# EFM32GG12B810F1024IL120 register map
File version: 3.0.0
CPU: CM4 r0p1, little endian, MPU, FPU, 3 interrupt priority bits
Registers are 32-bit, read-write, reset 0x0 unless marked. A register's access mark holds for its fields unless they carry their own. Offsets are from the block's base; [hi:lo] are bit positions; {n}, {i} and the like mark numbered series.

## SMU
Base 0x40020000
0x0C IF ro — Interrupt Flag Register
  [0] PPUPRIV — PPU Privilege Interrupt Flag
0x10 IFS wo — Interrupt Flag Set Register
  [0] PPUPRIV — Set PPUPRIV Interrupt Flag
0x14 IFC wo — Interrupt Flag Clear Register
  [0] PPUPRIV — Clear PPUPRIV Interrupt Flag
0x18 IEN — Interrupt Enable Register
  [0] PPUPRIV — PPUPRIV Interrupt Enable
0x40 PPUCTRL — PPU Control Register
  [0] ENABLE
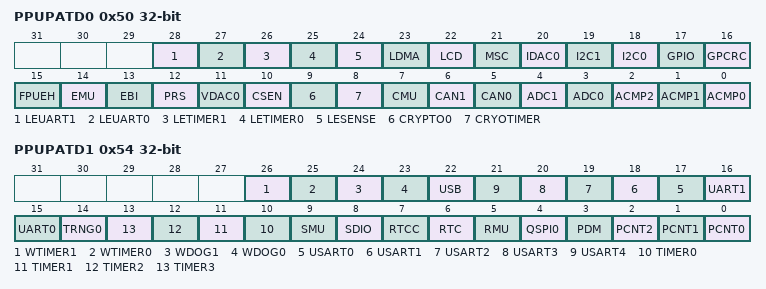
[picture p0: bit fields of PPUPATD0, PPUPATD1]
0x50 PPUPATD0 — PPU Privilege Access Type Descriptor 0
  [28] LEUART1 — Low Energy UART 1 access control bit
  [27] LEUART0 — Low Energy UART 0 access control bit
  [26] LETIMER1 — Low Energy Timer 1 access control bit
  [25] LETIMER0 — Low Energy Timer 0 access control bit
  [24] LESENSE — Low Energy Sensor Interface access control bit
  [23] LDMA — Linked Direct Memory Access Controller access control bit
  [22] LCD — Liquid Crystal Display Controller access control bit
  [21] MSC — Memory System Controller access control bit
  [20] IDAC0 — Current Digital to Analog Converter 0 access control bit
  [19] I2C1 — I2C 1 access control bit
  [18] I2C0 — I2C 0 access control bit
  [17] GPIO — General purpose Input/Output access control bit
  [16] GPCRC — General Purpose CRC access control bit
  [15] FPUEH — FPU Exception Handler access control bit
  [14] EMU — Energy Management Unit access control bit
  [13] EBI — External Bus Interface access control bit
  [12] PRS — Peripheral Reflex System access control bit
  [11] VDAC0 — Digital to Analog Converter 0 access control bit
  [10] CSEN — Capacitive touch sense module access control bit
  [9] CRYPTO0 — Advanced Encryption Standard Accelerator access control bit
  [8] CRYOTIMER — CRYOTIMER access control bit
  [7] CMU — Clock Management Unit access control bit
  [6] CAN1 — CAN 1 access control bit
  [5] CAN0 — CAN 0 access control bit
  [4] ADC1 — Analog to Digital Converter 0 access control bit
  [3] ADC0 — Analog to Digital Converter 0 access control bit
  [2] ACMP2 — Analog Comparator 2 access control bit
  [1] ACMP1 — Analog Comparator 1 access control bit
  [0] ACMP0 — Analog Comparator 0 access control bit
0x54 PPUPATD1 — PPU Privilege Access Type Descriptor 1
  [26] WTIMER1 — Wide Timer 0 access control bit
  [25] WTIMER0 — Wide Timer 0 access control bit
  [24] WDOG1 — Watchdog access control bit
  [23] WDOG0 — Watchdog access control bit
  [22] USB — Universal Serial Bus Interface access control bit
  [n+17] USART{n} (n=0..4) — Universal Synchronous/Asynchronous Receiver/Transmitter {n} access control bit
  [16] UART1 — Universal Asynchronous Receiver/Transmitter 1 access control bit
  [15] UART0 — Universal Asynchronous Receiver/Transmitter 0 access control bit
  [14] TRNG0 — True Random Number Generator 0 access control bit
  [n+10] TIMER{n} (n=0..3) — Timer {n} access control bit
  [9] SMU — Security Management Unit access control bit
  [8] SDIO — SDIO Controller access control bit
  [7] RTCC — Real-Time Counter and Calendar access control bit
  [6] RTC — Real-Time Counter access control bit
  [5] RMU — Reset Management Unit access control bit
  [4] QSPI0 — Quad-SPI access control bit
  [3] PDM — PDM Interface access control bit
  [2] PCNT2 — Pulse Counter 2 access control bit
  [1] PCNT1 — Pulse Counter 1 access control bit
  [0] PCNT0 — Pulse Counter 0 access control bit
0x58 PPUPATD2 reset not defined — PPU Privilege Access Type Descriptor 2
0x90 PPUFS ro — PPU Fault Status
  [6:0] PERIPHID
    0=ACMP0 (Analog Comparator 0); 1=ACMP1 (Analog Comparator 1); 2=ACMP2 (Analog Comparator 2); 3=ADC0 (Analog to Digital Converter 0); 4=ADC1 (Analog to Digital Converter 0); 5=CAN0; 6=CAN1; 7=CMU (Clock Management Unit); 8=CRYOTIMER; 9=CRYPTO0 (Advanced Encryption Standard Accelerator); 10=CSEN (Capacitive touch sense module); 11=VDAC0 (Digital to Analog Converter 0); 12=PRS (Peripheral Reflex System); 13=EBI (External Bus Interface); 14=EMU (Energy Management Unit); 15=FPUEH (FPU Exception Handler); 16=GPCRC (General Purpose CRC); 17=GPIO (General purpose Input/Output); 18=I2C0; 19=I2C1; 20=IDAC0 (Current Digital to Analog Converter 0); 21=MSC (Memory System Controller); 22=LCD (Liquid Crystal Display Controller); 23=LDMA (Linked Direct Memory Access Controller); 24=LESENSE (Low Energy Sensor Interface); 25=LETIMER0 (Low Energy Timer 0); 26=LETIMER1 (Low Energy Timer 1); 27=LEUART0 (Low Energy UART 0); 28=LEUART1 (Low Energy UART 1); 32=PCNT0 (Pulse Counter 0); 33=PCNT1 (Pulse Counter 1); 34=PCNT2 (Pulse Counter 2); 35=PDM (PDM Interface); 36=QSPI0 (Quad-SPI); 37=RMU (Reset Management Unit); 38=RTC (Real-Time Counter); 39=RTCC (Real-Time Counter and Calendar); 40=SDIO (SDIO Controller); 41=SMU (Security Management Unit); {v}=TIMER{v-42} (v=42..45); 46=TRNG0 (True Random Number Generator 0); 47=UART0 (Universal Asynchronous Receiver/Transmitter 0); 48=UART1 (Universal Asynchronous Receiver/Transmitter 1); {v}=USART{v-49} (Universal Synchronous/Asynchronous Receiver/Transmitter {v-49}) (v=49..53); 54=USB (Universal Serial Bus Interface); 55=WDOG0 (Watchdog); 56=WDOG1 (Watchdog); 57=WTIMER0 (Wide Timer 0); 58=WTIMER1 (Wide Timer 0)

## Notices in the file
# License
Copyright 2020 Silicon Laboratories Inc. www.silabs.com
SPDX-License-Identifier: Zlib
The licensor of this software is Silicon Laboratories Inc.
This software is provided 'as-is', without any express or implied
warranty. In no event will the authors be held liable for any damages
arising from the use of this software.
Permission is granted to anyone to use this software for any purpose,
including commercial applications, and to alter it and redistribute it
freely, subject to the following restrictions:
1. The origin of this software must not be misrepresented; you must not
claim that you wrote the original software. If you use this software
in a product, an acknowledgment in the product documentation would be
appreciated but is not required.
2. Altered source versions must be plainly marked as such, and must not be
misrepresented as being the original software.
3. This notice may not be removed or altered from any source distribution.
